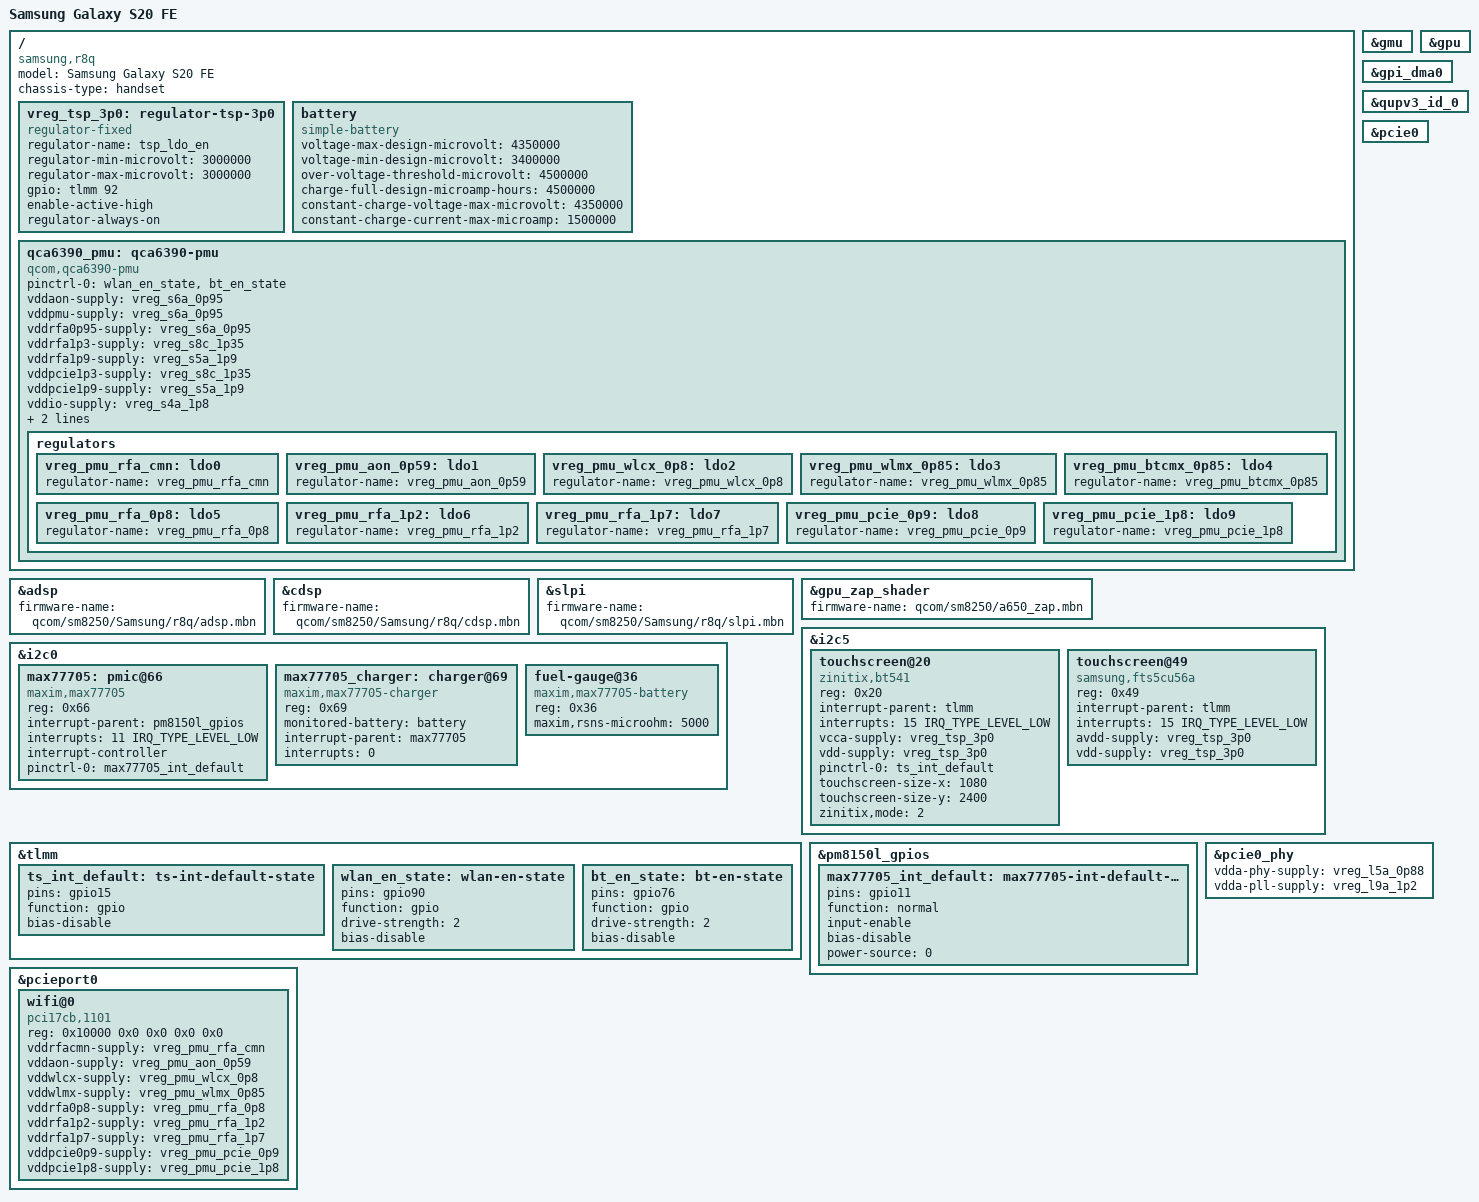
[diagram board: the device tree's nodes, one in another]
// SPDX-License-Identifier: GPL-2.0-only

/dts-v1/;

#include "sm8250-samsung-common.dtsi"

/ {
	model = "Samsung Galaxy S20 FE";
	compatible = "samsung,r8q", "qcom,sm8250";
	chassis-type = "handset";
};

&adsp {
	firmware-name = "qcom/sm8250/Samsung/r8q/adsp.mbn";
	status = "okay";
};

&cdsp {
	firmware-name = "qcom/sm8250/Samsung/r8q/cdsp.mbn";
	status = "okay";
};

&slpi {
	firmware-name = "qcom/sm8250/Samsung/r8q/slpi.mbn";
	status = "okay";
};

&gmu {
	status = "okay";
};

&gpu {
	status = "okay";
};

&gpu_zap_shader {
	/*
	 * Samsung-signed zap segments; the DT memory-region (gpu_mem
	 * carveout) is IGNORED at runtime via msm.r8q_zap_dyn=1 -- loading
	 * the zap at the carveout makes Samsung TZ hard-reset the SoC.
	 */
	firmware-name = "qcom/sm8250/a650_zap.mbn";
};

/ {
	/*
	 * TSP power: discrete LDO switched by TLMM 92 (downstream
	 * "tsp_ldo_en", fragment@177). The PMIC-LDO touch supplies seen in
	 * the qcom reference dtbo (st_fts@49 on se13) are NOT wired on r8q.
	 * always-on for bring-up so the bus can be probed at any time.
	 */
	vreg_tsp_3p0: regulator-tsp-3p0 {
		compatible = "regulator-fixed";
		regulator-name = "tsp_ldo_en";
		regulator-min-microvolt = <3000000>;
		regulator-max-microvolt = <3000000>;
		gpio = <&tlmm 92 GPIO_ACTIVE_HIGH>;
		enable-active-high;
		regulator-always-on;
	};

	/*
	 * EB-BG781ABY pack (4500 mAh typ). The MAX77705 charger driver only
	 * consumes voltage-max-design (it programs that as the CV float target);
	 * the rest is informational. 4350 mV float is a conservative, standard
	 * Li-ion CV -- below Samsung's stock 4380 mV -- for first bring-up.
	 */
	battery: battery {
		compatible = "simple-battery";
		voltage-max-design-microvolt = <4350000>;
		voltage-min-design-microvolt = <3400000>;
		over-voltage-threshold-microvolt = <4500000>;
		charge-full-design-microamp-hours = <4500000>;
		constant-charge-voltage-max-microvolt = <4350000>;
		constant-charge-current-max-microamp = <1500000>;
	};
};

/* SE5 has its FIFO interface disabled by firmware -- i2c5 is GPI-DMA-only. */
&gpi_dma0 {
	status = "okay";
};

&qupv3_id_0 {
	status = "okay";
};

&i2c5 {
	status = "okay";

	/*
	 * r8q ships two TSP variants (downstream fragment@178 on
	 * qupv3_se5_i2c, both status "ok"); only the fitted one ACKs.
	 * Zinitix ZT7650 is not in the mainline zinitix of_match; bt541 is
	 * a protocol-family guess. The 0x49 part is STM FTS5CU56A (Samsung
	 * "stm,fts_touch"); s6sy761/stmfts are the candidate protocols.
	 */
	touchscreen@20 {
		compatible = "zinitix,bt541";
		reg = <0x20>;
		interrupt-parent = <&tlmm>;
		interrupts = <15 IRQ_TYPE_LEVEL_LOW>;
		vcca-supply = <&vreg_tsp_3p0>;
		vdd-supply = <&vreg_tsp_3p0>;
		pinctrl-names = "default";
		pinctrl-0 = <&ts_int_default>;
		touchscreen-size-x = <1080>;
		touchscreen-size-y = <2400>;
		zinitix,mode = <2>;
	};

	touchscreen@49 {
		compatible = "samsung,fts5cu56a";
		reg = <0x49>;
		interrupt-parent = <&tlmm>;
		interrupts = <15 IRQ_TYPE_LEVEL_LOW>;
		avdd-supply = <&vreg_tsp_3p0>;
		vdd-supply = <&vreg_tsp_3p0>;
		/*
		 * NO touchscreen-size: the IC reports 0-4095 full-scale
		 * coordinates (downstream stm,max_coords), not pixels.
		 * Adding size-x/y 1080/2400 clamped the axes and broke GNOME
		 * touch mapping (verified live: worked without, broke with).
		 */
	};
};

&i2c0 {
	/*
	 * SE0 (qupv3_se0_i2c) carries the Maxim MAX77705 companion PMIC:
	 * charger/MUIC @0x66, and the ModelGauge m5 fuel gauge @0x36.
	 * For now only the fuel gauge is wired up -- read-only capacity /
	 * voltage via power-supply sysfs (maxim,max77705-battery is handled
	 * by the mainline max17042_battery driver). The max77705 MFD + charger
	 * are not in the config yet, so no charging control here.
	 * i2c-qcom-geni runs with r8q_force_fifo=1 globally, so SE0 uses the
	 * same FIFO-command + SE-DMA data path that makes SE5 (touch) work.
	 */
	status = "okay";

	/*
	 * MAX77705 top PMIC / MUIC + charger. This unit reports silicon rev
	 * PASS2 (0x2); mainline mfd/max77705.c only whitelisted PASS3, so it
	 * needs the r8q PASS2-accept patch (patches/0005) to probe. IRQ is on
	 * pm8150L gpio11, level-low (from the stock DT: irq-gpio pm8150l 0xb).
	 */
	max77705: pmic@66 {
		compatible = "maxim,max77705";
		reg = <0x66>;
		interrupt-parent = <&pm8150l_gpios>;
		interrupts = <11 IRQ_TYPE_LEVEL_LOW>;
		interrupt-controller;
		#interrupt-cells = <1>;
		pinctrl-names = "default";
		pinctrl-0 = <&max77705_int_default>;
	};

	max77705_charger: charger@69 {
		compatible = "maxim,max77705-charger";
		reg = <0x69>;
		monitored-battery = <&battery>;
		interrupt-parent = <&max77705>;
		interrupts = <0>;
	};

	/*
	 * ModelGauge fuel gauge -- left IRQ-less on purpose so the read-only
	 * telemetry keeps working even if the charger/MFD above fails to probe
	 * (the max17042 "Failed to get IRQ" dmesg lines are benign; it polls).
	 */
	fuel-gauge@36 {
		compatible = "maxim,max77705-battery";
		reg = <0x36>;
		maxim,rsns-microohm = <5000>;
	};
};

&tlmm {
	ts_int_default: ts-int-default-state {
		pins = "gpio15";
		function = "gpio";
		bias-disable;
	};

	/* QCA6390 WiFi/BT enable lines (driven by the qca6390-pmu). */
	wlan_en_state: wlan-en-state {
		pins = "gpio90";
		function = "gpio";
		drive-strength = <2>;
		bias-disable;
	};

	bt_en_state: bt-en-state {
		pins = "gpio76";
		function = "gpio";
		drive-strength = <2>;
		bias-disable;
	};
};

&pm8150l_gpios {
	max77705_int_default: max77705-int-default-state {
		pins = "gpio11";
		function = "normal";
		input-enable;
		bias-disable;
		power-source = <0>;
	};
};

/*
 * WiFi: QCA6390 over PCIe0 + ath11k. The qca6390-pmu power-sequences the chip
 * (POWER_SEQUENCING_QCOM_WCN) off the sm8250 rails and drives WLAN_EN (gpio90)
 * / BT_EN (gpio76), exposing the on-chip LDOs that feed the wifi@0 endpoint.
 * r8q GPIOs are from the stock DT (wl-en 0x5a, bt-en 0x4c).
 */
&pcie0 {
	status = "okay";
};

&pcie0_phy {
	vdda-phy-supply = <&vreg_l5a_0p88>;
	vdda-pll-supply = <&vreg_l9a_1p2>;
	status = "okay";
};

&pcieport0 {
	wifi@0 {
		compatible = "pci17cb,1101";
		reg = <0x10000 0x0 0x0 0x0 0x0>;

		vddrfacmn-supply = <&vreg_pmu_rfa_cmn>;
		vddaon-supply = <&vreg_pmu_aon_0p59>;
		vddwlcx-supply = <&vreg_pmu_wlcx_0p8>;
		vddwlmx-supply = <&vreg_pmu_wlmx_0p85>;
		vddrfa0p8-supply = <&vreg_pmu_rfa_0p8>;
		vddrfa1p2-supply = <&vreg_pmu_rfa_1p2>;
		vddrfa1p7-supply = <&vreg_pmu_rfa_1p7>;
		vddpcie0p9-supply = <&vreg_pmu_pcie_0p9>;
		vddpcie1p8-supply = <&vreg_pmu_pcie_1p8>;
	};
};

/ {
	qca6390_pmu: qca6390-pmu {
		compatible = "qcom,qca6390-pmu";

		pinctrl-names = "default";
		pinctrl-0 = <&wlan_en_state>, <&bt_en_state>;

		vddaon-supply = <&vreg_s6a_0p95>;
		vddpmu-supply = <&vreg_s6a_0p95>;
		vddrfa0p95-supply = <&vreg_s6a_0p95>;
		vddrfa1p3-supply = <&vreg_s8c_1p35>;
		vddrfa1p9-supply = <&vreg_s5a_1p9>;
		vddpcie1p3-supply = <&vreg_s8c_1p35>;
		vddpcie1p9-supply = <&vreg_s5a_1p9>;
		vddio-supply = <&vreg_s4a_1p8>;

		wlan-enable-gpios = <&tlmm 90 GPIO_ACTIVE_HIGH>;
		bt-enable-gpios = <&tlmm 76 GPIO_ACTIVE_HIGH>;

		regulators {
			vreg_pmu_rfa_cmn: ldo0 {
				regulator-name = "vreg_pmu_rfa_cmn";
			};
			vreg_pmu_aon_0p59: ldo1 {
				regulator-name = "vreg_pmu_aon_0p59";
			};
			vreg_pmu_wlcx_0p8: ldo2 {
				regulator-name = "vreg_pmu_wlcx_0p8";
			};
			vreg_pmu_wlmx_0p85: ldo3 {
				regulator-name = "vreg_pmu_wlmx_0p85";
			};
			vreg_pmu_btcmx_0p85: ldo4 {
				regulator-name = "vreg_pmu_btcmx_0p85";
			};
			vreg_pmu_rfa_0p8: ldo5 {
				regulator-name = "vreg_pmu_rfa_0p8";
			};
			vreg_pmu_rfa_1p2: ldo6 {
				regulator-name = "vreg_pmu_rfa_1p2";
			};
			vreg_pmu_rfa_1p7: ldo7 {
				regulator-name = "vreg_pmu_rfa_1p7";
			};
			vreg_pmu_pcie_0p9: ldo8 {
				regulator-name = "vreg_pmu_pcie_0p9";
			};
			vreg_pmu_pcie_1p8: ldo9 {
				regulator-name = "vreg_pmu_pcie_1p8";
			};
		};
	};
};
